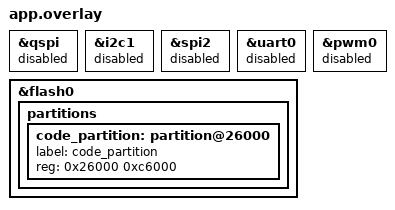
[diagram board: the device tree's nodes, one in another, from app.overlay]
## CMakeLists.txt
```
cmake_minimum_required(VERSION 3.20.0)
find_package(Zephyr REQUIRED HINTS $ENV{ZEPHYR_BASE})
project(hcirelay)

# Zephyr's own HCI controller sample, unchanged, plus the 1200 bps touch
target_sources(app PRIVATE ${ZEPHYR_BASE}/samples/bluetooth/hci_uart/src/main.c src/touch.c)
```

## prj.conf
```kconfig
# Zephyr's samples/bluetooth/hci_uart (prj.conf and its nRF52840 Dongle settings): an HCI controller on the USB serial
# port (H4), for a host stack on the Mac such as Bumble
CONFIG_CONSOLE=n
CONFIG_STDOUT_CONSOLE=n
CONFIG_UART_CONSOLE=n
CONFIG_GPIO=y
CONFIG_SERIAL=y
CONFIG_UART_INTERRUPT_DRIVEN=y
CONFIG_BT=y
CONFIG_BT_HCI_RAW=y
CONFIG_BT_HCI_RAW_H4=y
CONFIG_BT_HCI_RAW_H4_ENABLE=y
CONFIG_BT_BUF_ACL_RX_SIZE=255
CONFIG_BT_BUF_CMD_TX_SIZE=255
CONFIG_BT_BUF_EVT_DISCARDABLE_SIZE=255
CONFIG_BT_CTLR_ASSERT_HANDLER=y
CONFIG_BT_MAX_CONN=16
CONFIG_BT_TINYCRYPT_ECC=n
CONFIG_BT_CTLR_DTM_HCI=y
CONFIG_SYSTEM_WORKQUEUE_STACK_SIZE=512
CONFIG_BT_BUF_CMD_TX_COUNT=10
CONFIG_USB_DEVICE_STACK=y
CONFIG_USB_CDC_ACM=y
CONFIG_USB_DEVICE_INITIALIZE_AT_BOOT=n
CONFIG_USB_DEVICE_PRODUCT="LR HCI relay"
CONFIG_USB_DEVICE_MANUFACTURER="live-record"
# The Pro Micro clones' 32.768 kHz crystals run up to +125 ppm off: the calibrated RC works on any of them
CONFIG_CLOCK_CONTROL_NRF_K32SRC_RC=y
# src/touch.c
CONFIG_CDC_ACM_DTE_RATE_CALLBACK_SUPPORT=y
CONFIG_REBOOT=y
```

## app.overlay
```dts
/* Pro Micro nRF52840 (nice!nano and its clones) on the XIAO board definition, as firmware/selftest: the app after
 * S140 6.1.1 at 0x26000, for the Adafruit UF2 bootloader. */
&qspi { status = "disabled"; };
&i2c1 { status = "disabled"; };
&spi2 { status = "disabled"; };
&uart0 { status = "disabled"; };
&pwm0 { status = "disabled"; };

&flash0 {
	partitions {
		/delete-node/ partition@27000;
		code_partition: partition@26000 {
			label = "code_partition";
			reg = <0x26000 0xc6000>;
		};
	};
};
```

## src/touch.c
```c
// Opening the USB serial port at 1200 baud reboots into the UF2 bootloader (the Arduino "1200 bps touch"), so the
// relay is reflashed without a double-tap on reset. GPREGRET 0x57 is the Adafruit bootloader's UF2 magic.
#include <zephyr/drivers/uart/cdc_acm.h>
#include <zephyr/init.h>
#include <zephyr/sys/reboot.h>
#include <hal/nrf_power.h>

static void rate(const struct device *dev, uint32_t baud)
{
	if (baud == 1200) {
		nrf_power_gpregret_set(NRF_POWER, 0, 0x57);
		sys_reboot(SYS_REBOOT_WARM);
	}
}

static int touch_init(void)
{
	return cdc_acm_dte_rate_callback_set(DEVICE_DT_GET(DT_CHOSEN(zephyr_bt_c2h_uart)), rate);
}

SYS_INIT(touch_init, APPLICATION, 0);
```
